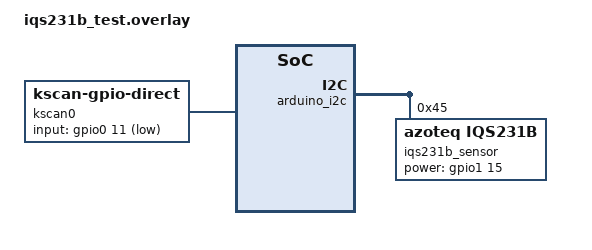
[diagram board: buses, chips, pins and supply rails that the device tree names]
/ {
	chosen {
		zmk,kscan = &kscan0;
	};

	kscan0: kscan {
		compatible = "zmk,kscan-gpio-direct";
		wakeup-source;

		input-gpios = <&gpio0 11 (GPIO_ACTIVE_LOW | GPIO_PULL_UP)>;
	};
};

&arduino_i2c {
	iqs231b_sensor: iqs231b@45 {
		compatible = "azoteq,iqs231b";
		reg = <0x45>;
		power-gpios = <&gpio1 15 GPIO_ACTIVE_HIGH>;

		proximity-threshold = <6>;            // 4, 6, 8, or 10 counts
		sample-rate-hz = <8>;               // 4, 8, 30, or 100 Hz
		quick-release-threshold = <50>;      // 50, 100, 150, or 250 counts
		quick-release-beta = <2>;             // 2=fast, 3=moderate, 4=moderate, 5=slow following.
		quick-release;
		// increase-debounce;                    // Enable increased debounce (12 in, 8 out)
		prox-with-movement;                   // Enable prox with movement UI instead of prox/no movement
		temperature-compensation;  // Enable temperature and interference compensation
	};
};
